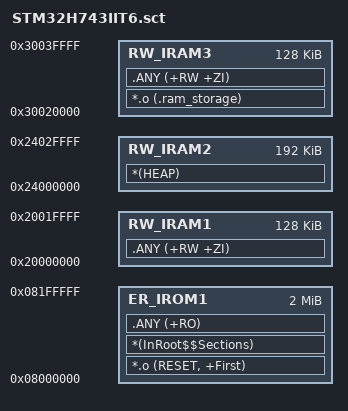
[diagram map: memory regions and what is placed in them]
; STM32H743IIT6 Scatter Loading File
; Heap placed in SRAM1, RAM storage in SRAM2

LR_IROM1 0x08000000 0x00200000  {    ; Load region size (2MB)
  ER_IROM1 0x08000000 0x00200000  {  ; Load address = Execution address
   *.o (RESET, +First)             ; Vector table
   *(InRoot$$Sections)             ; Sections in root
   .ANY (+RO)                      ; Code and RO data
  }
  
  RW_IRAM1 0x20000000 0x00020000  {  ; DTCM RAM (128KB) - Stack
   .ANY (+RW +ZI)                  ; RW and ZI data
  }

  RW_IRAM2 0x24000000 0x00030000  {  ; SRAM1 (192KB) - Heap
   *(HEAP)                         ; Heap (including ucHeap)
  }
  
  RW_IRAM3 0x30020000 0x00020000  {  ; SRAM2 (128KB) - SQLite RAM storage
   *.o (.ram_storage)             ; RAM storage section
   .ANY (+RW +ZI)                  ; Other RW/ZI data
  }
}
